VERSION ""

NS_ :

BS_:

BU_:

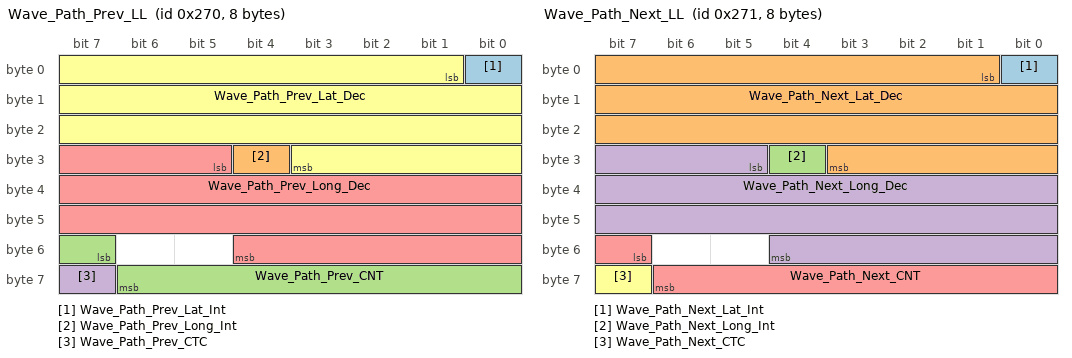
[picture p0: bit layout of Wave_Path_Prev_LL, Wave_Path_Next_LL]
BO_ 624 Wave_Path_Prev_LL: 8 Vector__XXX
 SG_ Wave_Path_Prev_Lat_Int : 0|1@1+ (1,37) [37|38] "" Vector__XXX
 SG_ Wave_Path_Prev_Long_Int : 28|1@1+ (1,126) [126|127] "" Vector__XXX
 SG_ Wave_Path_Prev_CNT : 55|8@1+ (1,0) [0|255] "" Vector__XXX
 SG_ Wave_Path_Prev_CTC : 63|1@1+ (1,0) [0|1] "" Vector__XXX
 SG_ Wave_Path_Prev_Long_Dec : 29|24@1+ (1,0) [0|10000000] "" Vector__XXX
 SG_ Wave_Path_Prev_Lat_Dec : 1|27@1+ (1,0) [0|100000000] "" Vector__XXX

BO_ 625 Wave_Path_Next_LL: 8 Vector__XXX
 SG_ Wave_Path_Next_Lat_Int : 0|1@1+ (1,37) [37|38] "" Vector__XXX
 SG_ Wave_Path_Next_Lat_Dec : 1|27@1+ (1,0) [0|100000000] "" Vector__XXX
 SG_ Wave_Path_Next_Long_Int : 28|1@1+ (1,126) [126|127] "" Vector__XXX
 SG_ Wave_Path_Next_Long_Dec : 29|24@1+ (1,0) [0|10000000] "" Vector__XXX
 SG_ Wave_Path_Next_CNT : 55|8@1+ (1,0) [0|255] "" Vector__XXX
 SG_ Wave_Path_Next_CTC : 63|1@1+ (1,0) [0|1] "" Vector__XXX

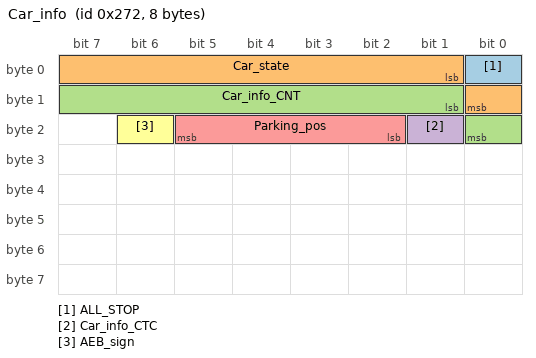
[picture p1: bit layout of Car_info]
BO_ 626 Car_info: 8 Vector__XXX
 SG_ ALL_STOP : 0|1@1+ (1,0) [0|1] "" Vector__XXX
 SG_ Car_state : 1|8@1+ (1,0) [0|255] "" Vector__XXX
 SG_ Car_info_CNT : 9|8@1+ (1,0) [0|255] "" Vector__XXX
 SG_ Car_info_CTC : 17|1@1+ (1,0) [0|1] "" Vector__XXX
 SG_ Parking_pos : 18|4@1+ (1,0) [0|7] "" Vector__XXX
 SG_ AEB_sign : 22|1@1+ (1,0) [0|1] "" Vector__XXX
